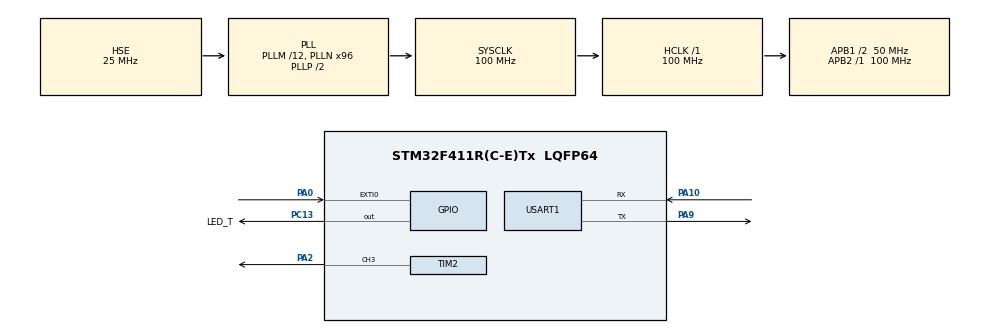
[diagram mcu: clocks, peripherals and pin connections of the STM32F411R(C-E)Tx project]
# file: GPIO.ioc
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Dma.Request0=USART1_RX
Dma.USART1_RX.0.Direction=DMA_PERIPH_TO_MEMORY
Dma.USART1_RX.0.FIFOMode=DMA_FIFOMODE_DISABLE
Dma.USART1_RX.0.Instance=DMA2_Stream2
Dma.USART1_RX.0.MemDataAlignment=DMA_MDATAALIGN_BYTE
Dma.USART1_RX.0.MemInc=DMA_MINC_ENABLE
Dma.USART1_RX.0.Mode=DMA_NORMAL
Dma.USART1_RX.0.PeriphDataAlignment=DMA_PDATAALIGN_BYTE
Dma.USART1_RX.0.PeriphInc=DMA_PINC_DISABLE
Dma.USART1_RX.0.Priority=DMA_PRIORITY_LOW
Mcu.Family=STM32F4
Mcu.Name=STM32F411R(C-E)Tx
Mcu.Package=LQFP64
NVIC.DMA2_Stream2_IRQn=true\:0\:0\:false\:false\:true\:false\:true\:true
NVIC.PriorityGroup=NVIC_PRIORITYGROUP_4
NVIC.TIM1_TRG_COM_TIM11_IRQn=true\:0\:0\:false\:false\:true\:true\:true\:true
NVIC.TIM2_IRQn=true\:0\:0\:false\:false\:true\:true\:true\:true
NVIC.USART1_IRQn=true\:0\:0\:false\:false\:true\:true\:true\:true
PA0-WKUP.GPIO_PuPd=GPIO_PULLUP
PA0-WKUP.Signal=GPXTI0
PA10.Mode=Asynchronous
PA10.Signal=USART1_RX
PA13.Mode=Serial_Wire
PA13.Signal=SYS_JTMS-SWDIO
PA14.Mode=Serial_Wire
PA14.Signal=SYS_JTCK-SWCLK
PA2.Signal=S_TIM2_CH3
PA9.Mode=Asynchronous
PA9.Signal=USART1_TX
PC13-ANTI_TAMP.GPIO_Label=LED_T
PC13-ANTI_TAMP.Signal=GPIO_Output
PC14-OSC32_IN.Mode=LSE-External-Oscillator
PC14-OSC32_IN.Signal=RCC_OSC32_IN
PC15-OSC32_OUT.Mode=LSE-External-Oscillator
PC15-OSC32_OUT.Signal=RCC_OSC32_OUT
PH0\ -\ OSC_IN.Mode=HSE-External-Oscillator
PH0\ -\ OSC_IN.Signal=RCC_OSC_IN
PH1\ -\ OSC_OUT.Mode=HSE-External-Oscillator
PH1\ -\ OSC_OUT.Signal=RCC_OSC_OUT
ProjectManager.HeapSize=0x800
ProjectManager.StackSize=0x800
ProjectManager.TargetToolchain=MDK-ARM V5.32
RCC.48MHZClocksFreq_Value=50000000
RCC.AHBFreq_Value=100000000
RCC.APB1CLKDivider=RCC_HCLK_DIV2
RCC.APB1Freq_Value=50000000
RCC.APB1TimFreq_Value=100000000
RCC.APB2Freq_Value=100000000
RCC.APB2TimFreq_Value=100000000
RCC.CortexFreq_Value=100000000
RCC.HCLKFreq_Value=100000000
RCC.HSE_VALUE=25000000
RCC.HSI_VALUE=16000000
RCC.PLLM=12
RCC.PLLN=96
RCC.PLLSourceVirtual=RCC_PLLSOURCE_HSE
RCC.SYSCLKFreq_VALUE=100000000
RCC.SYSCLKSource=RCC_SYSCLKSOURCE_PLLCLK
RCC.VCOOutputFreq_Value=200000000
SH.S_TIM2_CH3.0=TIM2_CH3,PWM Generation3 CH3
STMicroelectronics.X-CUBE-AI.10.2.1.ActivationBufferSizeList=120
STMicroelectronics.X-CUBE-AI.10.2.1.ActivationBuffers=pool0
STMicroelectronics.X-CUBE-AI.10.2.1.ActivationNames=pool0
STMicroelectronics.X-CUBE-AI.10.2.1.ActivationSizes=AI_GESTURE_CNN_DATA_ACTIVATION_1_SIZE
STMicroelectronics.X-CUBE-AI.10.2.1.ApplicationCcDeviceJjApplication=ApplicationTemplate
STMicroelectronics.X-CUBE-AI.10.2.1.HeapSize=0x800
STMicroelectronics.X-CUBE-AI.10.2.1.InternalRamActivationBufferMaxSize=AI_GESTURE_CNN_DATA_ACTIVATIONS_SIZE
STMicroelectronics.X-CUBE-AI.10.2.1.LatestDirectoryUsed-ca1b321f9fe014c71ff463b9908d85f1bb77f5dc2ea95bcf8c9175d2bab14249=D\:\\learn\\program\\5.CubeAI\\python_code
STMicroelectronics.X-CUBE-AI.10.2.1.MaximumNumberOfInputLayer=1
STMicroelectronics.X-CUBE-AI.10.2.1.MaximumNumberOfOutputLayer=1
STMicroelectronics.X-CUBE-AI.10.2.1.MaximumSizeOfInputLayer=1
STMicroelectronics.X-CUBE-AI.10.2.1.MaximumSizeOfOutputLayer=1
STMicroelectronics.X-CUBE-AI.10.2.1.ModelActualCompression-ca1b321f9fe014c71ff463b9908d85f1bb77f5dc2ea95bcf8c9175d2bab14249=0.0
STMicroelectronics.X-CUBE-AI.10.2.1.ModelCompression-ca1b321f9fe014c71ff463b9908d85f1bb77f5dc2ea95bcf8c9175d2bab14249=None
STMicroelectronics.X-CUBE-AI.10.2.1.ModelFlashOccupation-ca1b321f9fe014c71ff463b9908d85f1bb77f5dc2ea95bcf8c9175d2bab14249=1044
STMicroelectronics.X-CUBE-AI.10.2.1.ModelHashList=ca1b321f9fe014c71ff463b9908d85f1bb77f5dc2ea95bcf8c9175d2bab14249
STMicroelectronics.X-CUBE-AI.10.2.1.ModelKind-ca1b321f9fe014c71ff463b9908d85f1bb77f5dc2ea95bcf8c9175d2bab14249=KERAS
STMicroelectronics.X-CUBE-AI.10.2.1.ModelMacc-ca1b321f9fe014c71ff463b9908d85f1bb77f5dc2ea95bcf8c9175d2bab14249=561
STMicroelectronics.X-CUBE-AI.10.2.1.ModelName-ca1b321f9fe014c71ff463b9908d85f1bb77f5dc2ea95bcf8c9175d2bab14249=gesture_cnn
STMicroelectronics.X-CUBE-AI.10.2.1.ModelNameList=gesture_cnn
STMicroelectronics.X-CUBE-AI.10.2.1.ModelRamOccupation-ca1b321f9fe014c71ff463b9908d85f1bb77f5dc2ea95bcf8c9175d2bab14249=120
STMicroelectronics.X-CUBE-AI.10.2.1.ModelStructureFile-ca1b321f9fe014c71ff463b9908d85f1bb77f5dc2ea95bcf8c9175d2bab14249=D\:\\learn\\program\\5.CubeAI\\python_code\\sine_calcu.h5
STMicroelectronics.X-CUBE-AI.10.2.1.ModelType-ca1b321f9fe014c71ff463b9908d85f1bb77f5dc2ea95bcf8c9175d2bab14249=STM32Cube.AI MCU runtime
STMicroelectronics.X-CUBE-AI.10.2.1.ReadyForCodeGeneration=true
STMicroelectronics.X-CUBE-AI.10.2.1.StackSize=0x800
STMicroelectronics.X-CUBE-AI.10.2.1.WorkingBufferStartAddrList=0xFFFFFFFF
STMicroelectronics.X-CUBE-AI.10.2.1.XAaCUBEAaAICcArtificialOoIntelligenceJjCore=true
STMicroelectronics.X-CUBE-AI.10.2.1.copyWeightToRam-ca1b321f9fe014c71ff463b9908d85f1bb77f5dc2ea95bcf8c9175d2bab14249=false
STMicroelectronics.X-CUBE-AI.10.2.1.customLayerConfigEnabled-ca1b321f9fe014c71ff463b9908d85f1bb77f5dc2ea95bcf8c9175d2bab14249=false
STMicroelectronics.X-CUBE-AI.10.2.1.noOnnxIoTranspose-ca1b321f9fe014c71ff463b9908d85f1bb77f5dc2ea95bcf8c9175d2bab14249=false
STMicroelectronics.X-CUBE-AI.10.2.1.useInputAllocation-ca1b321f9fe014c71ff463b9908d85f1bb77f5dc2ea95bcf8c9175d2bab14249=true
STMicroelectronics.X-CUBE-AI.10.2.1.useOutputAllocation-ca1b321f9fe014c71ff463b9908d85f1bb77f5dc2ea95bcf8c9175d2bab14249=true
TIM11.Period=999
TIM11.Prescaler=99
TIM2.Channel-PWM\ Generation3\ CH3=TIM_CHANNEL_3
TIM2.OCMode_PWM-PWM\ Generation3\ CH3=TIM_OCMODE_PWM1
TIM2.Period=999
TIM2.Prescaler=99
TIM2.Pulse-PWM\ Generation3\ CH3=300
USART1.VirtualMode=VM_ASYNC
VP_STMicroelectronics.X-CUBE-AI_VS_ArtificialOoIntelligenceJjXAaCUBEAaAI_10.2.1.Mode=ArtificialOoIntelligenceJjXAaCUBEAaAI
VP_STMicroelectronics.X-CUBE-AI_VS_DeviceJjApplication_10.2.1.Mode=DeviceJjApplication
VP_TIM11_VS_ClockSourceINT.Mode=Enable_Timer
board=custom

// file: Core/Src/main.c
/* USER CODE BEGIN Header */
/**
  ******************************************************************************
  * @file           : main.c
  * @brief          : Main program body
  ******************************************************************************
  * @attention
  *
  * Copyright (c) 2026 STMicroelectronics.
  * All rights reserved.
  *
  * This software is licensed under terms that can be found in the LICENSE file
  * in the root directory of this software component.
  * If no LICENSE file comes with this software, it is provided AS-IS.
  *
  ******************************************************************************
  */
/* USER CODE END Header */
#include "main.h"
#include "dma.h"
#include "tim.h"
#include "usart.h"
#include "gpio.h"
#include "app_x-cube-ai.h"

/* USER CODE BEGIN Includes */
#include "stdio.h"
#include "string.h"
#include "stm32f4xx_it.h"
/* USER CODE END Includes */

/* USER CODE BEGIN PV */
//接收缓冲区
extern uint8_t RXbuf[50];
//定时器计数变量
uint16_t pwm_val = 0;
//呼吸方向
//1:递增
//-1:递减
int8_t breath_dir = 1;
/* USER CODE END PV */

void SystemClock_Config(void);

int main(void)
{

  /* MCU Configuration--------------------------------------------------------*/

  /* Reset of all peripherals, Initializes the Flash interface and the Systick. */
  HAL_Init();

  /* Configure the system clock */
  SystemClock_Config();

  /* Initialize all configured peripherals */
  MX_GPIO_Init();
  MX_DMA_Init();
  MX_USART1_UART_Init();
  MX_TIM11_Init();
  MX_TIM2_Init();
  MX_X_CUBE_AI_Init();
  /* USER CODE BEGIN 2 */
  //接收DMA初始化
  HAL_UART_Receive_DMA(&huart1, RXbuf, 50);
  //接收DMA中断使能
  __HAL_UART_ENABLE_IT(&huart1, UART_IT_IDLE);

  //启动TIM11定时器
  HAL_TIM_Base_Start_IT(&htim11);

	//启动PWM输出 通道3
	HAL_TIM_PWM_Start(&htim2, TIM_CHANNEL_3);

  /* USER CODE END 2 */

  /* Infinite loop */
  while (1)
  {

  MX_X_CUBE_AI_Process();
  }
}

void SystemClock_Config(void)
{
  RCC_OscInitTypeDef RCC_OscInitStruct = {0};
  RCC_ClkInitTypeDef RCC_ClkInitStruct = {0};

  /** Configure the main internal regulator output voltage
  */
  __HAL_RCC_PWR_CLK_ENABLE();
  __HAL_PWR_VOLTAGESCALING_CONFIG(PWR_REGULATOR_VOLTAGE_SCALE1);

  /** Initializes the RCC Oscillators according to the specified parameters
  * in the RCC_OscInitTypeDef structure.
  */
  RCC_OscInitStruct.OscillatorType = RCC_OSCILLATORTYPE_HSE;
  RCC_OscInitStruct.HSEState = RCC_HSE_ON;
  RCC_OscInitStruct.PLL.PLLState = RCC_PLL_ON;
  RCC_OscInitStruct.PLL.PLLSource = RCC_PLLSOURCE_HSE;
  RCC_OscInitStruct.PLL.PLLM = 12;
  RCC_OscInitStruct.PLL.PLLN = 96;
  RCC_OscInitStruct.PLL.PLLP = RCC_PLLP_DIV2;
  RCC_OscInitStruct.PLL.PLLQ = 4;
  if (HAL_RCC_OscConfig(&RCC_OscInitStruct) != HAL_OK)
  {
    Error_Handler();
  }

  /** Initializes the CPU, AHB and APB buses clocks
  */
  RCC_ClkInitStruct.ClockType = RCC_CLOCKTYPE_HCLK|RCC_CLOCKTYPE_SYSCLK
                              |RCC_CLOCKTYPE_PCLK1|RCC_CLOCKTYPE_PCLK2;
  RCC_ClkInitStruct.SYSCLKSource = RCC_SYSCLKSOURCE_PLLCLK;
  RCC_ClkInitStruct.AHBCLKDivider = RCC_SYSCLK_DIV1;
  RCC_ClkInitStruct.APB1CLKDivider = RCC_HCLK_DIV2;
  RCC_ClkInitStruct.APB2CLKDivider = RCC_HCLK_DIV1;

  if (HAL_RCC_ClockConfig(&RCC_ClkInitStruct, FLASH_LATENCY_3) != HAL_OK)
  {
    Error_Handler();
  }
}

void Error_Handler(void)
{
  __disable_irq();
  while (1)
  {
  }
}
